# FM33FH0XX register map
File version: 1.0
CPU: SC000 r1p0, little endian, no MPU, no FPU, 3 interrupt priority bits
Registers are 32-bit, read-write, reset 0x0 unless marked. A register's access mark holds for its fields unless they carry their own. Offsets are from the block's base; [hi:lo] are bit positions.

## UART0 — UART0 module information
Base 0x40011C00
Same registers: UART1 0x40012000, UART2 0x40017400, UART3 0x40017800, UART4 0x4001A000, UART5 0x4001A400
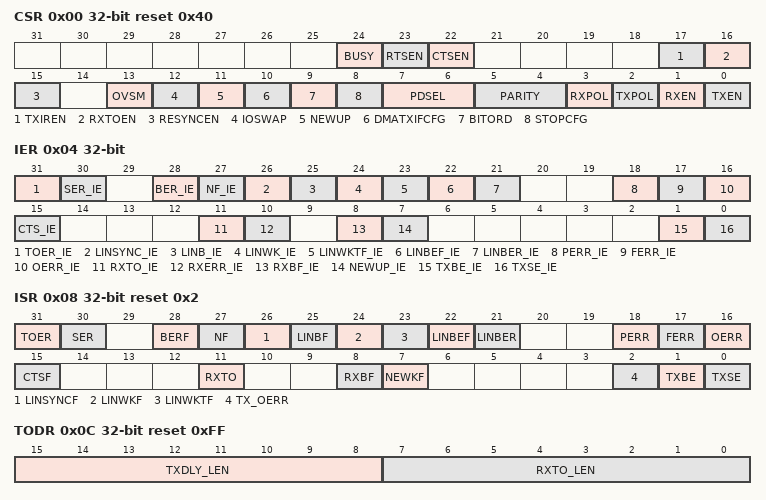
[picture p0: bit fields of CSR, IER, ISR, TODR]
0x00 CSR reset 0x40
  [24] BUSY ro — BUSY field description
  [23] RTSEN — RTSEN field description
  [22] CTSEN — CTSEN field description
  [17] TXIREN — TXIREN field description
  [16] RXTOEN — RXTOEN field description
  [15] RESYNCEN — RESYNCEN field description
  [13] OVSM — OVSM field description
  [12] IOSWAP — IOSWAP field description
  [11] NEWUP — NEWUP field description
  [10] DMATXIFCFG — DMATXIFCFG field description
  [9] BITORD — BITORD field description
  [8] STOPCFG — STOPCFG field description
  [7:6] PDSEL — PDSEL field description
  [5:4] PARITY — PARITY field description
  [3] RXPOL — RXPOL field description
  [2] TXPOL — TXPOL field description
  [1] RXEN — RXEN field description
  [0] TXEN — TXEN field description
0x04 IER
  [31] TOER_IE — TOER_IE field description
  [30] SER_IE — SER_IE field description
  [28] BER_IE — BER_IE field description
  [27] NF_IE — NF_IE field description
  [26] LINSYNC_IE — LINSYNC_IE field description
  [25] LINB_IE — LINB_IE field description
  [24] LINWK_IE — LINWK_IE field description
  [23] LINWKTF_IE — LINWKTF_IE field description
  [22] LINBEF_IE — LINBEF_IE field description
  [21] LINBER_IE — LINBER_IE field description
  [18] PERR_IE — PERR_IE field description
  [17] FERR_IE — FERR_IE field description
  [16] OERR_IE — OERR_IE field description
  [15] CTS_IE — CTS_IE field description
  [11] RXTO_IE — RXTO_IE field description
  [10] RXERR_IE — RXERR_IE field description
  [8] RXBF_IE — RXBF_IE field description
  [7] NEWUP_IE — NEWUP_IE field description
  [1] TXBE_IE — TXBE_IE field description
  [0] TXSE_IE — TXSE_IE field description
0x08 ISR reset 0x2
  [31] TOER — TOER field description
  [30] SER — SER field description
  [28] BERF — BERF field description
  [27] NF — NF field description
  [26] LINSYNCF — LINSYNCF field description
  [25] LINBF — LINBF field description
  [24] LINWKF — LINWKF field description
  [23] LINWKTF — LINWKTF field description
  [22] LINBEF — LINBEF field description
  [21] LINBER — LINBER field description
  [18] PERR — PERR field description
  [17] FERR — FERR field description
  [16] OERR — OERR field description
  [15] CTSF — CTSF field description
  [11] RXTO — RXTO field description
  [8] RXBF — RXBF field description
  [7] NEWKF — NEWKF field description
  [2] TX_OERR — TX_OERR field description
  [1] TXBE ro — TXBE field description
  [0] TXSE — TXSE field description
0x0C TODR reset 0xFF
  [15:8] TXDLY_LEN — TXDLY_LEN field description
  [7:0] RXTO_LEN — RXTO_LEN field description
0x10 RXBUF
  [8:0] RXBUF ro — RXBUF field description
0x14 TXBUF
  [8:0] TXBUF wo — TXBUF field description
0x18 BRG reset 0x341
  [15:0] SPBRG — SPBRG field description
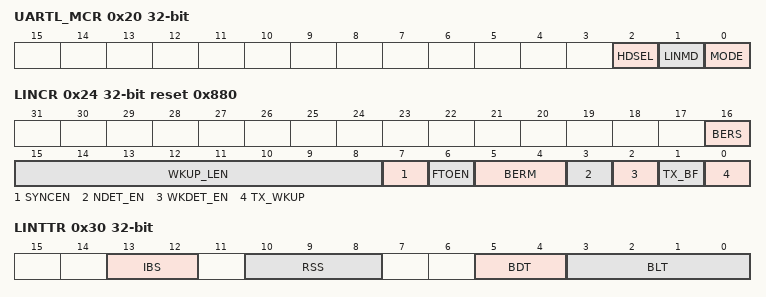
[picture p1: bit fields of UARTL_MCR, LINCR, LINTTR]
0x20 UARTL_MCR
  [2] HDSEL — HDSEL field description
  [1] LINMD — LINMD field description
  [0] MODE — MODE field description
0x24 LINCR reset 0x880
  [16] BERS — BERS field description
  [15:8] WKUP_LEN — WKUP_LEN field description
  [7] SYNCEN — SYNCEN field description
  [6] FTOEN — FTOEN field description
  [5:4] BERM — BERM field description
  [3] NDET_EN — NDET_EN field description
  [2] WKDET_EN — WKDET_EN field description
  [1] TX_BF — TX_BF field description
  [0] TX_WKUP — TX_WKUP field description
0x28 LINBSR
  [19:0] BAUD_SYNC ro — BAUD_SYNC field description
0x2C LINFTR reset 0xFF
  [11:0] FTO — FTO field description
0x30 LINTTR
  [13:12] IBS — IBS field description
  [10:8] RSS — RSS field description
  [5:4] BDT — BDT field description
  [3:0] BLT — BLT field description
0x34 LINPSR
  [19:0] PRE_SYNC ro — PRE_SYNC field description
0x38 LINBKR
  [27:0] BREAK_LEN ro — BREAK_LEN field description
0x80 LINSCCR
  [2:0] LINSTC — LINSTC field description
